# ATmega328PB device description
Architecture: AVR8; Family: megaAVR
Registers are 8-bit, access not given, no defined reset value unless marked. A register's access mark holds for its fields unless they carry their own. Offsets are from the block's base; [hi:lo] are bit positions.

## LOCKBIT
Instances: LOCKBIT 0 in lockbits
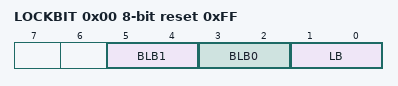
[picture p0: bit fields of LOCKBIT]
0x00 LOCKBIT reset 0xFF
  [5:4] BLB1 — Boot Loader Protection Mode
    0=LPM_SPM_DISABLE (LPM and SPM prohibited in Boot Section); 1=LPM_DISABLE (LPM prohibited in Boot Section); 2=SPM_DISABLE (SPM prohibited in Boot Section); 3=NO_LOCK (No lock on SPM and LPM in Boot Section)
  [3:2] BLB0 — Boot Loader Protection Mode
    0=LPM_SPM_DISABLE (LPM and SPM prohibited in Application Section); 1=LPM_DISABLE (LPM prohibited in Application Section); 2=SPM_DISABLE (SPM prohibited in Application Section); 3=NO_LOCK (No lock on SPM and LPM in Application Section)
  [1:0] LB — Memory Lock
    0=PROG_VER_DISABLED (Further programming and verification disabled); 2=PROG_DISABLED (Further programming disabled); 3=NO_LOCK (No memory lock features enabled)

## USART0
Instances: USART0 0x00
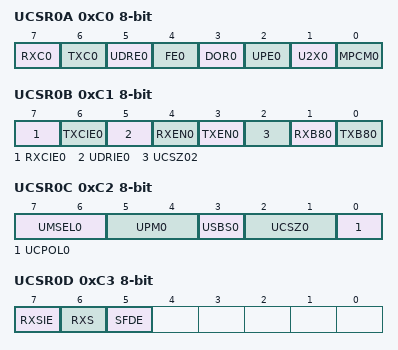
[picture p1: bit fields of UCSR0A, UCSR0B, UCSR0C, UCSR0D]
0xC0 UCSR0A — USART Control and Status Register A
  [7] RXC0 — USART Receive Complete
  [6] TXC0 — USART Transmitt Complete
  [5] UDRE0 — USART Data Register Empty
  [4] FE0 — Framing Error
  [3] DOR0 — Data overRun
  [2] UPE0 — Parity Error
  [1] U2X0 — Double the USART transmission speed
  [0] MPCM0 — Multi-processor Communication Mode
0xC1 UCSR0B — USART Control and Status Register B
  [7] RXCIE0 — RX Complete Interrupt Enable
  [6] TXCIE0 — TX Complete Interrupt Enable
  [5] UDRIE0 — USART Data register Empty Interrupt Enable
  [4] RXEN0 — Receiver Enable
  [3] TXEN0 — Transmitter Enable
  [2] UCSZ02 — Character Size
  [1] RXB80 — Receive Data Bit 8
  [0] TXB80 — Transmit Data Bit 8
0xC2 UCSR0C — USART Control and Status Register C
  [7:6] UMSEL0 — USART Mode Select
    0=Asynchronous USART; 1=Synchronous USART; 3=Master SPI
  [5:4] UPM0 — Parity Mode Bits
    0=Disabled; 2=Enabled, Even Parity; 3=Enabled, Odd Parity
  [3] USBS0 — Stop Bit Select
    0=1-bit; 1=2-bit
  [2:1] UCSZ0 — Character Size
  [0] UCPOL0 — Clock Polarity
0xC3 UCSR0D — USART Control and Status Register D
  [7] RXSIE — USART RX Start Interrupt Enable
  [6] RXS — USART RX Start
  [5] SFDE — Start frame detection enable
0xC4 UBRR0 16-bit bits used 11:0 — USART Baud Rate Register Bytes
0xC6 UDR0 — USART I/O Data Register 0

## USART1
Instances: USART1 0x00
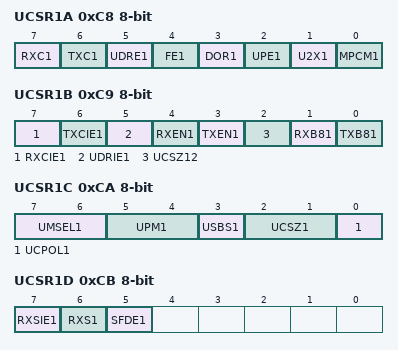
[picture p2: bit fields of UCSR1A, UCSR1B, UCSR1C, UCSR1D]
0xC8 UCSR1A — USART Control and Status Register A
  [7] RXC1 — USART Receive Complete
  [6] TXC1 — USART Transmitt Complete
  [5] UDRE1 — USART Data Register Empty
  [4] FE1 — Framing Error
  [3] DOR1 — Data overRun
  [2] UPE1 — Parity Error
  [1] U2X1 — Double the USART transmission speed
  [0] MPCM1 — Multi-processor Communication Mode
0xC9 UCSR1B — USART Control and Status Register B
  [7] RXCIE1 — RX Complete Interrupt Enable
  [6] TXCIE1 — TX Complete Interrupt Enable
  [5] UDRIE1 — USART Data register Empty Interrupt Enable
  [4] RXEN1 — Receiver Enable
  [3] TXEN1 — Transmitter Enable
  [2] UCSZ12 — Character Size
  [1] RXB81 — Receive Data Bit 8
  [0] TXB81 — Transmit Data Bit 8
0xCA UCSR1C — USART Control and Status Register C
  [7:6] UMSEL1 — USART Mode Select
    0=Asynchronous USART; 1=Synchronous USART; 3=Master SPI
  [5:4] UPM1 — Parity Mode Bits
    0=Disabled; 2=Enabled, Even Parity; 3=Enabled, Odd Parity
  [3] USBS1 — Stop Bit Select
    0=1-bit; 1=2-bit
  [2:1] UCSZ1 — Character Size
  [0] UCPOL1 — Clock Polarity
0xCB UCSR1D — USART Control and Status Register D
  [7] RXSIE1 — USART RX Start Interrupt Enable
  [6] RXS1 — USART RX Start
  [5] SFDE1 — Start frame detection enable
0xCC UBRR1 16-bit bits used 11:0 — USART Baud Rate Register Bytes
0xCE UDR1 — USART I/O Data Register

## TWI0
Instances: TWI0 0x00
0xB8 TWBR0 — TWI Bit Rate register
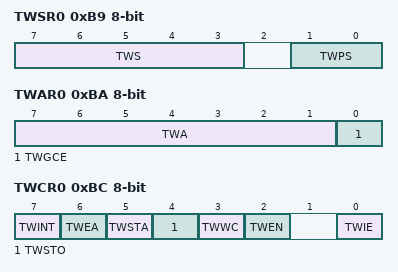
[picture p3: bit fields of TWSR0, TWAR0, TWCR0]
0xB9 TWSR0 — TWI Status Register
  [7:3] TWS (bit 3 of the value upward) — TWI Status
  [1:0] TWPS — TWI Prescaler
    0=1; 1=4; 2=16; 3=64
0xBA TWAR0 — TWI (Slave) Address register
  [7:1] TWA — TWI (Slave) Address register Bits
  [0] TWGCE — TWI General Call Recognition Enable Bit
0xBB TWDR0 — TWI Data register
0xBC TWCR0 — TWI Control Register
  [7] TWINT — TWI Interrupt Flag
  [6] TWEA — TWI Enable Acknowledge Bit
  [5] TWSTA — TWI Start Condition Bit
  [4] TWSTO — TWI Stop Condition Bit
  [3] TWWC — TWI Write Collition Flag
  [2] TWEN — TWI Enable Bit
  [0] TWIE — TWI Interrupt Enable
0xBD TWAMR0 — TWI (Slave) Address Mask Register
  [7:1] TWAM
